# RL6955_IP_SVD register map
Vendor: Realtek
Registers are 32-bit, read-write, reset 0x0 unless marked. A register's access mark holds for its fields unless they carry their own. Offsets are from the block's base; [hi:lo] are bit positions; <NAME> marks a mode.

## PAGE5_ON
Base 0x40000000
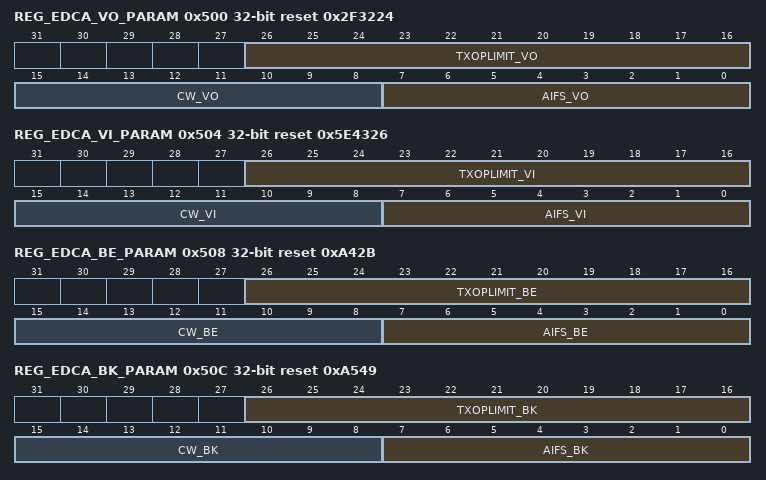
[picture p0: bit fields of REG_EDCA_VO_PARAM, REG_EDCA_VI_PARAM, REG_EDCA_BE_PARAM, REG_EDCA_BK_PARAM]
0x500 REG_EDCA_VO_PARAM reset 0x2F3224
  [26:16] TXOPLIMIT_VO — TXOP Limit An unsigned integer in units of 32 microseconds. Value of zero indicates that a single MSDU or MMPDU in addition to a protection frame exchange can be transmitted at any rate. Default: BK = 0h; BE = 0h; VI = 5Eh; VO = 2Fh.
  [15:8] CW_VO — ECWmin and ECWmax encode the values of Cwmin and Cwmax respectively in an exponent form. Ex: Cwmax = 2^(ECWmax)-1 Default: BK = Ah/5h; BE = Ah/5h; VI = 5h/4h; VO = 4h/3h.
  [7:0] AIFS_VO — Arbitrary Inter frame space In unit of microsecond. AIFS indicates the time a non-AP QSTA should defer before either invoking a backoff or starting a transmission Default: BK = 49h; BE = 25h; VI = 1Ch; VO = 1Ch.
0x504 REG_EDCA_VI_PARAM reset 0x5E4326
  [26:16] TXOPLIMIT_VI — TXOP Limit An unsigned integer in units of 32 microseconds. Value of zero indicates that a single MSDU or MMPDU in addition to a protection frame exchange can be transmitted at any rate. Default: BK = 0h; BE = 0h; VI = 5Eh; VO = 2Fh.
  [15:8] CW_VI — ECWmin and ECWmax encode the values of Cwmin and Cwmax respectively in an exponent form. Ex: Cwmax = 2^(ECWmax)-1 Default: BK = Ah/5h; BE = Ah/5h; VI = 5h/4h; VO = 4h/3h.
  [7:0] AIFS_VI — Arbitrary Inter frame space In unit of microsecond. AIFS indicates the time a non-AP QSTA should defer before either invoking a backoff or starting a transmission Default: BK = 49h; BE = 25h; VI = 1Ch; VO = 1Ch.
0x508 REG_EDCA_BE_PARAM reset 0xA42B
  [26:16] TXOPLIMIT_BE — TXOP Limit An unsigned integer in units of 32 microseconds. Value of zero indicates that a single MSDU or MMPDU in addition to a protection frame exchange can be transmitted at any rate. Default: BK = 0h; BE = 0h; VI = 5Eh; VO = 2Fh.
  [15:8] CW_BE — ECWmin and ECWmax encode the values of Cwmin and Cwmax respectively in an exponent form. Ex: Cwmax = 2^(ECWmax)-1 Default: BK = Ah/5h; BE = Ah/5h; VI = 5h/4h; VO = 4h/3h.
  [7:0] AIFS_BE — Arbitrary Inter frame space In unit of microsecond. AIFS indicates the time a non-AP QSTA should defer before either invoking a backoff or starting a transmission Default: BK = 49h; BE = 25h; VI = 1Ch; VO = 1Ch.
0x50C REG_EDCA_BK_PARAM reset 0xA549
  [26:16] TXOPLIMIT_BK — TXOP Limit An unsigned integer in units of 32 microseconds. Value of zero indicates that a single MSDU or MMPDU in addition to a protection frame exchange can be transmitted at any rate. Default: BK = 0h; BE = 0h; VI = 5Eh; VO = 2Fh.
  [15:8] CW_BK — ECWmin and ECWmax encode the values of Cwmin and Cwmax respectively in an exponent form. Ex: Cwmax = 2^(ECWmax)-1 Default: BK = Ah/5h; BE = Ah/5h; VI = 5h/4h; VO = 4h/3h.
  [7:0] AIFS_BK — Arbitrary Inter frame space In unit of microsecond. AIFS indicates the time a non-AP QSTA should defer before either invoking a backoff or starting a transmission Default: BK = 49h; BE = 25h; VI = 1Ch; VO = 1Ch.
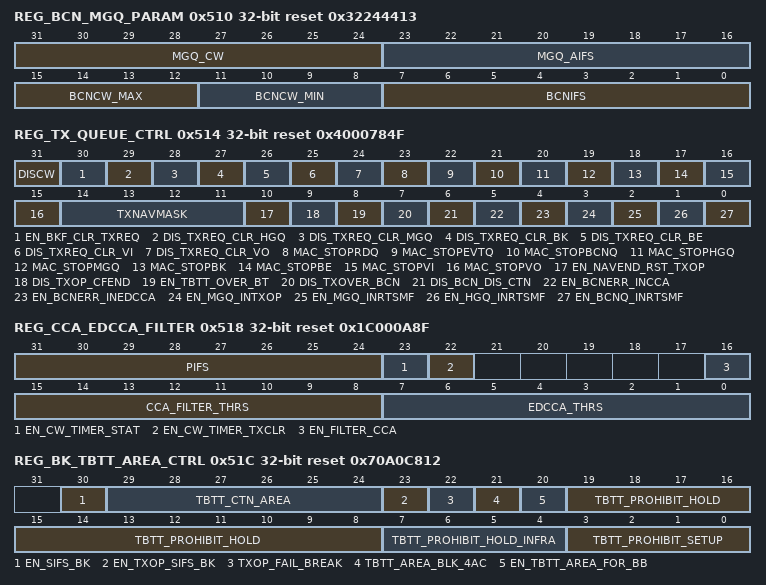
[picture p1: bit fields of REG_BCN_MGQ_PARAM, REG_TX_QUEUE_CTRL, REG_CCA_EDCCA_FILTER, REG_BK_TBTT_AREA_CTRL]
0x510 REG_BCN_MGQ_PARAM reset 0x32244413
  [31:24] MGQ_CW — ECWmin and ECWmax encode the values of Cwmin and Cwmax respectively in an exponent form. Ex: Cwmax = 2^(ECWmax)-1 Default: BK = Ah/5h; BE = Ah/5h; VI = 5h/4h; VO = 4h/3h.
  [23:16] MGQ_AIFS — Arbitrary Inter frame space In unit of microsecond. AIFS indicates the time a non-AP QSTA should defer before either invoking a backoff or starting a transmission Default: BK = 49h; BE = 25h; VI = 1Ch; VO = 1Ch
  [15:12] BCNCW_MAX — Beacon Contention Window MAX Defines the contention window value for back off before transmitting beacon frame. This field is set to 0 in AP mode to indicate no back off window. In ad hoc mode, its default value is 6. 26-1 = 63 time slots.
  [11:8] BCNCW_MIN — Beacon Contention Window Defines the contention window value for back off before transmitting beacon frame. This field is set to 0 in AP mode to indicate no back off window. In ad hoc mode, its default value is 6. 26-1 = 63 time slots.
  [7:0] BCNIFS — Beacon Interframe Space In units of microseconds, this register defines the medium idle time required before transmitting beacon (AP mode) or entering random back off window.
0x514 REG_TX_QUEUE_CTRL reset 0x4000784F
  [31] DISCW — When this bit is set, disable CW.
  [30] EN_BKF_CLR_TXREQ — when gen tx command done, while will backoff is invalid, then tx command will be cleared
  [29] DIS_TXREQ_CLR_HGQ — 1: if this queue can't own channel ,txcmd will be cleared 0:Only TX_finish can clear txreq
  [28] DIS_TXREQ_CLR_MGQ — 1: if this queue can't own channel ,txcmd will be cleared 0:Only TX_finish can clear txreq
  [27] DIS_TXREQ_CLR_BK — 0: if this queue can't own channel ,txcmd will be cleared 1:Only TX_finish can clear txreq
  [26] DIS_TXREQ_CLR_BE — 0: if this queue can't own channel ,txcmd will be cleared 1:Only TX_finish can clear txreq
  [25] DIS_TXREQ_CLR_VI — 0: if this queue can't own channel ,txcmd will be cleared 1:Only TX_finish can clear txreq
  [24] DIS_TXREQ_CLR_VO — 0: if this queue can't own channel ,txcmd will be cleared 1:Only TX_finish can clear txreq
  [23] MAC_STOPRDQ — Stop BCNQ Queue Write a 1 to this bit via software to immediately stop the transmission of packet from this queue including retry attempts.
  [22] MAC_STOPEVTQ — Stop BCNQ Queue Write a 1 to this bit via software to immediately stop the transmission of packet from this queue including retry attempts.
  [21] MAC_STOPBCNQ — Stop BCNQ Queue Write a 1 to this bit via software to immediately stop the transmission of packet from this queue including retry attempts.
  [20] MAC_STOPHGQ — Stop High Queue Write a 1 to this bit via software to immediately stop the transmission of packet from this queue including retry attempts.
  [19] MAC_STOPMGQ — Stop Management Queue Write a 1 to this bit via software to immediately stop the transmission of packet from this queue including retry attempts.
  [18] MAC_STOPBK — Stop BK Queue Write a 1 to this bit via software to immediately stop the transmission of packet from this queue including retry attempts.
  [17] MAC_STOPBE — Stop BE Queue Write a 1 to this bit via software to immediately stop the transmission of packet from this queue including retry attempts.
  [16] MAC_STOPVI — Stop VI Queue Write a 1 to this bit via software to immediately stop the transmission of packet from this queue including retry attempts.
  [15] MAC_STOPVO — Stop VO Queue Write a 1 to this bit via software to immediately stop the transmission of packet from this queue including retry attempts.
  [14:11] TXNAVMASK — 1: Queue BKF must wait TX Nav finished 0: Queue not need wait
  [10] EN_NAVEND_RST_TXOP — When set this bit, TXOP will be reset while NAV end.
  [9] DIS_TXOP_CFEND — Disable TXOP_CFE function
  [8] EN_TBTT_OVER_BT — 1: Enable Beacon Tx at TBTT if BT_CCA is enabled 0: Disable
  [7] DIS_TXOVER_BCN — 1: Tx Packet with ignoring Beacon Area time 0: Disable
  [6] DIS_BCN_DIS_CTN — Disable the Beacon queue disable contention,when set to 0 enable the force beacon function.
  [5] EN_BCNERR_INCCA — eneble force tx becon ignore CCA in disable contention area
  [4] EN_BCNERR_INEDCCA — eneble force tx becon ignore EDCCA in disable contention area
  [3] EN_MGQ_INTXOP — When this bit is set, MGTQ may sent packets by using ACQ TXOP.
  [2] EN_MGQ_INRTSMF — When this bit is set, MTGQ will be TX, not wait until RTS or MF transaction finished.
  [1] EN_HGQ_INRTSMF — When this bit is set, High Q will be TX, not wait until RTS or MF transaction finished.
  [0] EN_BCNQ_INRTSMF — When this bit is set, BCNQ will be TX, not wait until RTS or MF transaction finished.
0x518 REG_CCA_EDCCA_FILTER reset 0x1C000A8F
  [31:24] PIFS — PIFS time. It is only used in AP mode and in units of us.
  [23] EN_CW_TIMER_STAT — 1: enable contention time statistic of ACQ
  [22] EN_CW_TIMER_TXCLR — 1: clear cw timer when any queue tx 0: don't clear cw timer when other queue tx
  [16] EN_FILTER_CCA — Enable CCA filter threshold
  [15:8] CCA_FILTER_THRS — If PHY_CCA signal width is bigger than this threshold, this PHY_CCA signal is valid for MAC. Unit: us
  [7:0] EDCCA_THRS — EDCCA threshold value, edcca over this threshold will cause bkf_rst Bit[7]: PHY_EDCCA為1時,當timer timeout時擋住TX Bit[6:0]: timer (單位:32us)
0x51C REG_BK_TBTT_AREA_CTRL reset 0x70A0C812
  [30] EN_SIFS_BK — SIFS Break Check Criteria enable for AMPDU aggregation, for normal AGGR case
  [29:24] TBTT_CTN_AREA — TBTT contention area,Time unit is 128us,for PORT 1 / 2
  [23] EN_TXOP_SIFS_BK — SIFS Break Check Criteria enable for AMPDU aggregation, VALID when TXOP or RTS HOLD
  [22] TXOP_FAIL_BREAK — 1: if tx pkt fail in txop, then tx cfend to end txop
  [21] TBTT_AREA_BLK_4AC — When set this bit, 4AC backoff is disabled on TBTT setup period
  [20] EN_TBTT_AREA_FOR_BB — enable notify bb that mac p0 is in tbtt area
  [19:8] TBTT_PROHIBIT_HOLD — TBTT_prohibit_hold time for AP mode, unit is 32 us
  [7:4] TBTT_PROHIBIT_HOLD_INFRA — TBTT_prohibit_hold time for infrastructure mode , unit is 2 ms
  [3:0] TBTT_PROHIBIT_SETUP — TBTT_prohibit_setup, unit is 32us; If en nan-CG, this value should be set to 0x06.
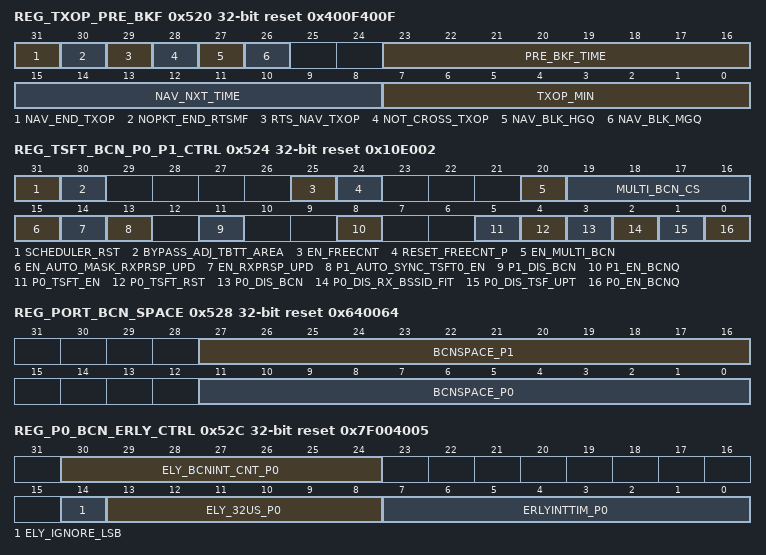
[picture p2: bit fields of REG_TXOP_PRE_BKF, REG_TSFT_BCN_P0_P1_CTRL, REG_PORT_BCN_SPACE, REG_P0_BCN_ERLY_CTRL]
0x520 REG_TXOP_PRE_BKF reset 0x400F400F
  [31] NAV_END_TXOP — 1: In txop mode, Nav protect all txop 0: In txop mode, Nav protect to next pkt
  [30] NOPKT_END_RTSMF — 1: enable exit rts hold mode when there is no corresponding ac pkt to tx
  [29] RTS_NAV_TXOP — enable RTS NAV protect all txop
  [28] NOT_CROSS_TXOP — 1:tx pkt cross tbtt is prohibited 0:tx pkt cross tbtt is permitted
  [27] NAV_BLK_HGQ — rxnav block HGQ
  [26] NAV_BLK_MGQ — rxnav block MGQ
  [23:16] PRE_BKF_TIME — when bkf timer count down this value, sel queue and gen txcmd will start. Unit: 1us
  [15:8] NAV_NXT_TIME — In TXOP mode ,NAV setting which protects next packets
  [7:0] TXOP_MIN — if txop counter is more than this value, than tx pkt is considered not cross tbtt. Unit: 1us
0x524 REG_TSFT_BCN_P0_P1_CTRL access per field reset 0x10E002
  [31] SCHEDULER_RST wo — Write this bit reset scheduler, ioreg_txfail
  [30] BYPASS_ADJ_TBTT_AREA rw — 0: Fixed an issue where tbtt_area kept pulling higher caused by tbtt_int miss 1: follow the original practice
  [25] EN_FREECNT rw — enable freerun tsft
  [24] RESET_FREECNT_P wo — reset pulse of freerun tsft
  [20] EN_MULTI_BCN rw — enable multiple beacons of port0~port2
  [19:16] MULTI_BCN_CS ro — indicate which port is tx beacon
  [15] EN_AUTO_MASK_RXPRSP_UPD rw — valid when BIT_EN_RXPRSP_UPD = 1 1: auto disable RXPRSP's tsft update when rx probe response frame during bcn_early to tbtt(for STA mode - P0)
  [14] EN_RXPRSP_UPD rw — 1: enable update tsft when RX probe response frame. (for STA mode - P0)
  [13] P1_AUTO_SYNC_TSFT0_EN rw — when P0 + P1 is concurrent mode, need to assert 1: sync P1's TSFT = P0's TSFT + TSFTF_SYN_OFFSET each time 0: P1's TSFT = P0's TSFT
  [11] P1_DIS_BCN rw — set 1 to mask the beacon early interrupt of port1
  [8] P1_EN_BCNQ rw — When this bit is set, TSF and other beacon related functions are then enabled. 0x700(MACID1)的enable开关
  [5] P0_TSFT_EN rw — 1: enable P0 TSFT counter, when NAN function is disable, P1 used P0 TSFT counter
  [4] P0_TSFT_RST wo — write this bit, bcn0 tsft will auto reset, reset to 1
  [3] P0_DIS_BCN rw — set 1 to mask the beacon early interrupt of port0
  [2] P0_DIS_RX_BSSID_FIT rw — 0:HW will handle rx_beacon 1:HW will ignore rx_beacon_pk
  [1] P0_DIS_TSF_UPT rw — When set, disable port 0 TSF update when beacon frames or probe response frames are received.
  [0] P0_EN_BCNQ rw — enable beacon function. When this bit is set, TSF and other beacon related functions are then enabled. 0x610(MACID)的enable开关
0x528 REG_PORT_BCN_SPACE reset 0x640064
  [27:16] BCNSPACE_P1 — Unit is ms. the beacon space of port1
  [11:0] BCNSPACE_P0 — Unit is ms. the beacon space of port0
0x52C REG_P0_BCN_ERLY_CTRL reset 0x7F004005
  [30:24] ELY_BCNINT_CNT_P0 — Be used in multiple BCNIVL early INT. When this counter =1, multiple BCNIVL early INT will be triggered.
  [14] ELY_IGNORE_LSB — 1:add1ms, add128us, add32us only check tsft[10], tsft[7], tsft[5], ignore LSB 0: add1ms, add128us, add32us check tsft[9:0], tsft[6:0], tsft[4:0] when active
  [13:8] ELY_32US_P0 — the BCN EARLY interrupt find tune with unit 32us. The Total Early time of BCN early interrupt is the ERLYINTTIM x 1ms - EARLY_32us x 32us.
  [7:0] ERLYINTTIM_P0 — Time to send interrupt to notify driver to change beacon content. Time unit is TU. It is used to wake up early at DriverEarlyTime
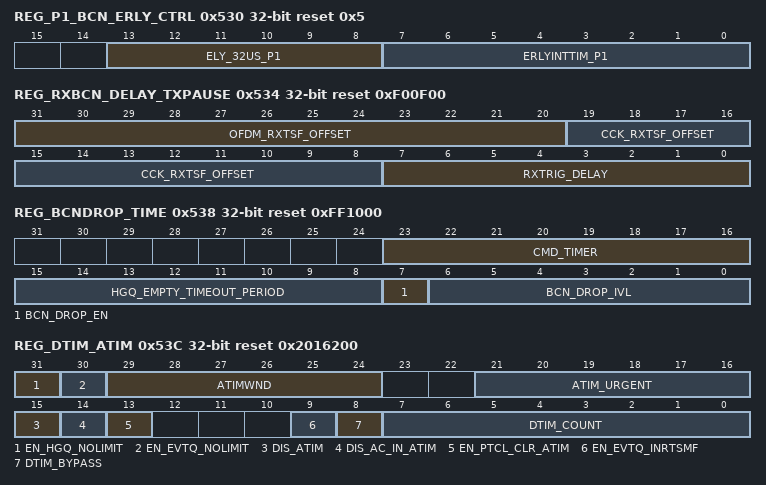
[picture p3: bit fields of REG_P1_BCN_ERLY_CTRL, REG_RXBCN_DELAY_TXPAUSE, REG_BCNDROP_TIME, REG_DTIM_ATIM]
0x530 REG_P1_BCN_ERLY_CTRL reset 0x5
  [13:8] ELY_32US_P1 — the BCN EARLY interrupt find tune with unit 32us. The Total Early time of BCN early interrupt is the ERLYINTTIM x 1ms - EARLY_32us x 32us.
  [7:0] ERLYINTTIM_P1 — Time to send interrupt to notify driver to change beacon content. Time unit is TU. It is used to wake up early at DriverEarlyTime
0x534 REG_RXBCN_DELAY_TXPAUSE reset 0xF00F00
  [31:20] OFDM_RXTSF_OFFSET — The Datapath of OFDM RX_tsf, unit: us
  [19:8] CCK_RXTSF_OFFSET — The Datapath of CCK RX_tsf, unit: us
  [7:0] RXTRIG_DELAY — add compensation of RX trigger's TSFT. Unit: us
0x538 REG_BCNDROP_TIME reset 0xFF1000
  [23:16] CMD_TIMER — When 40M/80M TX CMD ready and secondary_CCA_20/secondary_CCA_40 set for this period, then the TX CMD will be cleared. TU: 1us
  [15:8] HGQ_EMPTY_TIMEOUT_PERIOD — When hgq empty for this period, close atim window. And this will block hgq dma for pcie, unless 0x524[12] set enable. TU: 32us
  [7] BCN_DROP_EN — enable beacon drop function
  [6:0] BCN_DROP_IVL — indicate the timeout of beacon drop
0x53C REG_DTIM_ATIM reset 0x2016200
  [31] EN_HGQ_NOLIMIT — enable no limit mode of hgq
  [30] EN_EVTQ_NOLIMIT — enable no limit mode of evtq
  [29:24] ATIMWND — ATIM window width of P1 TX hgq in units of TU.
  [21:16] ATIM_URGENT — Indicates the time before ATIM Window end. (unit : TU)
  [15] DIS_ATIM — 1: disable assert ATIM
  [14] DIS_AC_IN_ATIM — 1: Disable AC Queue Packet Tx in ATIM (only valid at Nettype: Adhoc/AP) 0: Enable AC Queue packet Tx in ATIM
  [13] EN_PTCL_CLR_ATIM — 1: enable fw_clr_sch_atim signal to clear atimon (means this is the last hgq packet)
  [9] EN_EVTQ_INRTSMF — When this bit is set, Event Q will be TX, not wait until RTS or MF transaction finished.
  [8] DTIM_BYPASS — 1: dtim counter will keep 0
  [7:0] DTIM_COUNT — init dtim value, act on the port of apmode
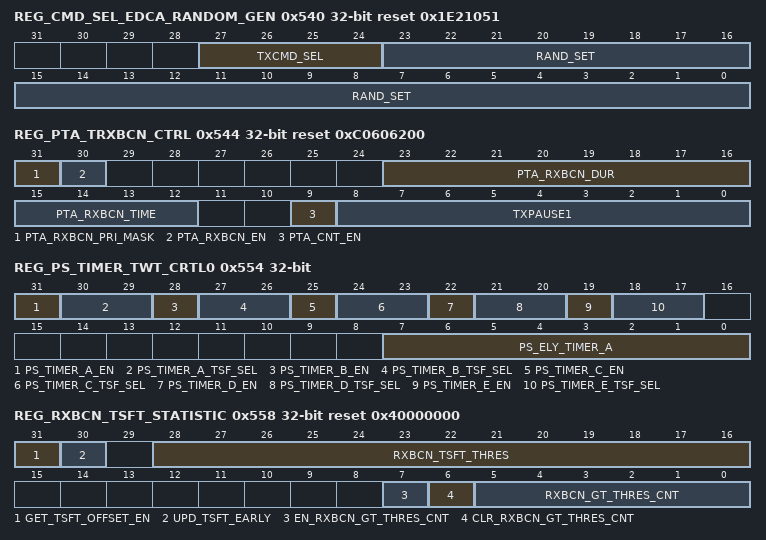
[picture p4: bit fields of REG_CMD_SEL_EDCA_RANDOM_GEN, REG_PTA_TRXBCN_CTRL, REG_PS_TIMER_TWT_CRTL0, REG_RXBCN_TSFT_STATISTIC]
0x540 REG_CMD_SEL_EDCA_RANDOM_GEN reset 0x1E21051
  [27:24] TXCMD_SEL — [HW Debug Info]To select which one TXCMD Segment. For example, 可以在0x5CF[3:0]填 0 or 6 讀取 0x5F8[7:0] : Tx Agg 0x5F9[7:0] : Tx Rate
  [23:0] RAND_SET — Random number generator polynomial
0x544 REG_PTA_TRXBCN_CTRL reset 0xC0606200
  [31] PTA_RXBCN_PRI_MASK
  [30] PTA_RXBCN_EN
  [23:16] PTA_RXBCN_DUR — unit: 32us. Period of wl_rxbcn
  [15:12] PTA_RXBCN_TIME — unit: 32us. Assert wl_rxbcn before TBTT
  [9] PTA_CNT_EN — When change mode, need to count down before exit BT_MODE
  [8:0] TXPAUSE1 — same as 0x514[23:15], allow FW/DR to control pause jointly
0x548 REG_PS_TIMER_A
  [31:0] PS_TIMER_A — When the TSF matches the content of this register, the PS_TIMER_A_INT interrupt is issued. Unit:16us
0x54C REG_PS_TIMER_B
  [31:0] PS_TIMER_B — When the TSF matches the content of this register, the PS_TIMER_B_INT interrupt is issued. Unit:16us
0x550 REG_PS_TIMER_C
  [31:0] PS_TIMER_C — When the TSF matches the content of this register, the PS_TIMER_C_INT interrupt is issued. Unit:16us
0x554 REG_PS_TIMER_TWT_CRTL0
  [31] PS_TIMER_A_EN — Enable PS_TIMER_A
  [30:29] PS_TIMER_A_TSF_SEL — 0 for port 0, 1 for freerun, 2 for p2 backup
  [28] PS_TIMER_B_EN — Enable PS_TIMER_B
  [27:26] PS_TIMER_B_TSF_SEL — 0 for port 0, 1 for freerun, 2 for p2 backup
  [25] PS_TIMER_C_EN — Enable PS_TIMER_C
  [24:23] PS_TIMER_C_TSF_SEL — 0 for port 0, 1 for freerun, 2 for p2 backup
  [22] PS_TIMER_D_EN — Enable PS_TIMER_D
  [21:20] PS_TIMER_D_TSF_SEL — 0 for port 0, 1 for freerun, 2 for p2 backup
  [19] PS_TIMER_E_EN — Enable PS_TIMER_E
  [18:17] PS_TIMER_E_TSF_SEL — 0 for port 0, 1 for freerun, 2 for p2 backup
  [7:0] PS_ELY_TIMER_A — It is used to wake up early at PS_Timer_A_Early Time. Time unit is 32us.
0x558 REG_RXBCN_TSFT_STATISTIC access per field reset 0x40000000
  [31] GET_TSFT_OFFSET_EN rw — 1: Enable Enable get TSFT offset function
  [30] UPD_TSFT_EARLY rw — 0: don't update TSFT when the following scenarios occur: tim_no_hit, |TSFT - rxbcn.timestamp| <= BIT_RXBCN_TSFT_THRES, and r_wait_rxbcn_finish = 1 1: update TSFT
  [28:16] RXBCN_TSFT_THRES rw — used for LPS MAC, if |TSFT - rxbcn.timestamp| > BIT_RXBCN_TSFT_THRES, need to wait fcsok. Else, update TSFT at wmac_rxtsf_rdy (before fcsok) unit is 1us,max is 8ms
  [7] EN_RXBCN_GT_THRES_CNT rw — enable the counter of BIT_RXBCN_GT_THRES_CNT
  [6] CLR_RXBCN_GT_THRES_CNT wo — clear the BIT_RXBCN_GT_THRES_CNT to 0
  [5:0] RXBCN_GT_THRES_CNT ro — valid when BIT_EN_RXBCN_GT_THRES_CNT = 1. counter the number of beacon with the |TSFT - rxbcn.timestamp| exceed the threshold
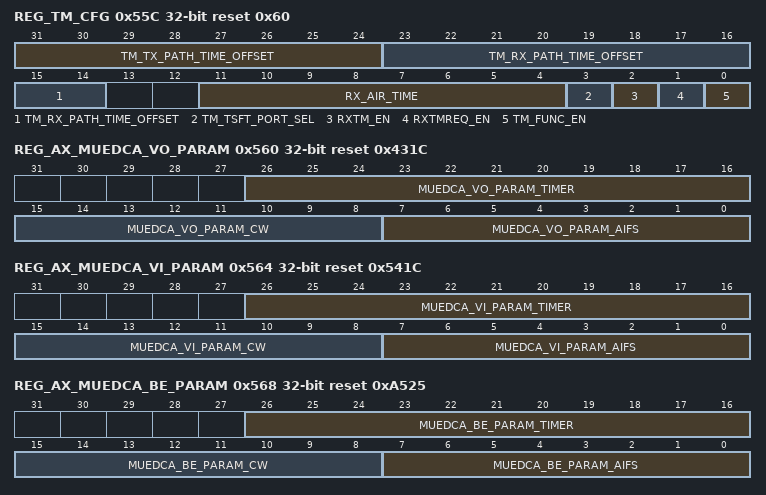
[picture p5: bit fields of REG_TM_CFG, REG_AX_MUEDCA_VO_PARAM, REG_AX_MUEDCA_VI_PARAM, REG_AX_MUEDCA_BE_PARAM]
0x55C REG_TM_CFG reset 0x60
  [31:24] TM_TX_PATH_TIME_OFFSET — Compensate the time, from PHYTXON rising edge to transmit antenna connector. unit: 1us
  [23:14] TM_RX_PATH_TIME_OFFSET — Compensate the time, from receive antenna connector to DATAON rising edge. unit: 1us
  [11:4] RX_AIR_TIME — This register sets the time from cca fall to 6us. unit: 1us. (default:6us)
  [3] TM_TSFT_PORT_SEL — selected TM timer port 0: port0; 1: freerun
  [2] RXTM_EN — 1: HW will parsing rx packet, to find TM frame
  [1] RXTMREQ_EN — 1: HW will parsing rx packet, to find TM request frame
  [0] TM_FUNC_EN — 1: Enable Timing Measurement function
0x560 REG_AX_MUEDCA_VO_PARAM reset 0x431C
  [26:16] MUEDCA_VO_PARAM_TIMER — MU EDCA TIMER, in units of 1ms Note: SPEC: The MU EDCA Timer field (8b) indicates the duration of time, in units of 8 TUs
  [15:8] MUEDCA_VO_PARAM_CW — ECWmin and ECWmax encode the values of Cwmin and Cwmax respectively in an exponent form. Ex: Cwmax = 2^(ECWmax)-1 Default: BK = Ah/5h; BE = Ah/5h; VI = 5h/4h; VO = 4h/3h.
  [7:0] MUEDCA_VO_PARAM_AIFS — Arbitrary Inter frame space In unit of microsecond. AIFS indicates the time a non-AP QSTA should defer before either invoking a backoff or starting a transmission Default: BK = 49h; BE = 25h; VI = 1Ch; VO = 1Ch.
0x564 REG_AX_MUEDCA_VI_PARAM reset 0x541C
  [26:16] MUEDCA_VI_PARAM_TIMER — MU EDCA TIMER, in units of 1ms Note: SPEC: The MU EDCA Timer field (8b) indicates the duration of time, in units of 8 TUs
  [15:8] MUEDCA_VI_PARAM_CW — ECWmin and ECWmax encode the values of Cwmin and Cwmax respectively in an exponent form. Ex: Cwmax = 2^(ECWmax)-1 Default: BK = Ah/5h; BE = Ah/5h; VI = 5h/4h; VO = 4h/3h.
  [7:0] MUEDCA_VI_PARAM_AIFS — Arbitrary Inter frame space In unit of microsecond. AIFS indicates the time a non-AP QSTA should defer before either invoking a backoff or starting a transmission Default: BK = 49h; BE = 25h; VI = 1Ch; VO = 1Ch.
0x568 REG_AX_MUEDCA_BE_PARAM reset 0xA525
  [26:16] MUEDCA_BE_PARAM_TIMER — MU EDCA TIMER, in units of 1ms Note: SPEC: The MU EDCA Timer field (8b) indicates the duration of time, in units of 8 TUs
  [15:8] MUEDCA_BE_PARAM_CW — ECWmin and ECWmax encode the values of Cwmin and Cwmax respectively in an exponent form. Ex: Cwmax = 2^(ECWmax)-1 Default: BK = Ah/5h; BE = Ah/5h; VI = 5h/4h; VO = 4h/3h.
  [7:0] MUEDCA_BE_PARAM_AIFS — Arbitrary Inter frame space In unit of microsecond. AIFS indicates the time a non-AP QSTA should defer before either invoking a backoff or starting a transmission Default: BK = 49h; BE = 25h; VI = 1Ch; VO = 1Ch.
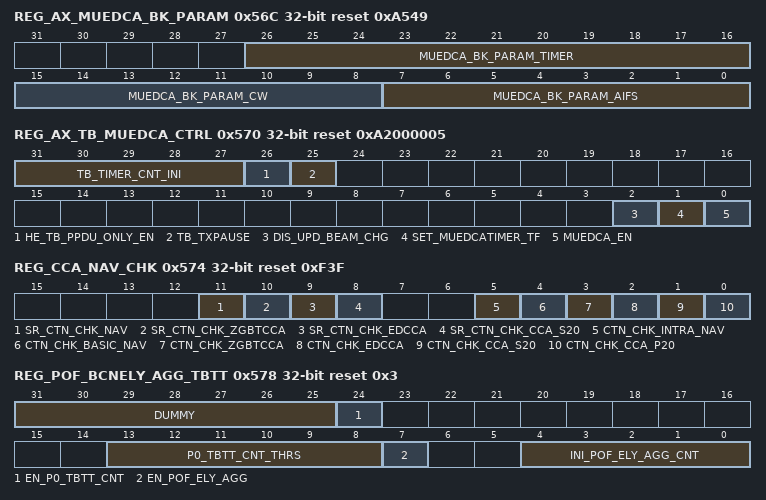
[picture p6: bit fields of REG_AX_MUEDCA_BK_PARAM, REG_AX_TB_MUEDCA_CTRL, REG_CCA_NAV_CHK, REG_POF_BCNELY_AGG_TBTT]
0x56C REG_AX_MUEDCA_BK_PARAM reset 0xA549
  [26:16] MUEDCA_BK_PARAM_TIMER — MU EDCA TIMER, in units of 1ms Note: SPEC: The MU EDCA Timer field (8b) indicates the duration of time, in units of 8 TUs
  [15:8] MUEDCA_BK_PARAM_CW — ECWmin and ECWmax encode the values of Cwmin and Cwmax respectively in an exponent form. Ex: Cwmax = 2^(ECWmax)-1 Default: BK = Ah/5h; BE = Ah/5h; VI = 5h/4h; VO = 4h/3h.
  [7:0] MUEDCA_BK_PARAM_AIFS — Arbitrary Inter frame space In unit of microsecond. AIFS indicates the time a non-AP QSTA should defer before either invoking a backoff or starting a transmission Default: BK = 49h; BE = 25h; VI = 1Ch; VO = 1Ch.
0x570 REG_AX_TB_MUEDCA_CTRL reset 0xA2000005
  [31:27] TB_TIMER_CNT_INI — the initial value of th_timer, unit: us
  [26] HE_TB_PPDU_ONLY_EN — asserted if the TWT is trigger-enabled TWT
  [25] TB_TXPAUSE — valid if BIT_HE_TB_PPSU_ONLY_EN = 1; select pause edca or not during TWT-SP; default is 1, pause. A TWT requesting STA should not transmit frames to the TWT responding STA outside of negotiated TWT SPs and should not transmit frames that are not contained within HE TB PPDUs to the TWT responding STA within trigger-enabled TWT SPs
  [2] DIS_UPD_BEAM_CHG — 1: txcmd_beam_change TIE 0 0: first PPDU in TXOP will assert txcmd_beam_change
  [1] SET_MUEDCATIMER_TF — 1: enable HW updating MUEDCATimer after Tx HE TB PPDU 0: disable HW updating MUEDCATimer after Tx HE TB PPDU
  [0] MUEDCA_EN — 1: enable HW updating MUEDCATimer 0: disable HW updating MUEDCATimer
0x574 REG_CCA_NAV_CHK reset 0xF3F
  [11] SR_CTN_CHK_NAV — When BASIC or INTRA NAV > 0 in the AIFS/Backoff before active TX 0: Can backoff, can TX 1: Cannot backoff, cannot TX
  [10] SR_CTN_CHK_ZGBTCCA — When ~GNT_WL(BT/ZigBee) assert in the AIFS/Backoff before active TX 0: Can backoff, can TX 1: Cannot backoff, cannot TX
  [9] SR_CTN_CHK_EDCCA — When EDCCA assert in the AIFS/Backoff before active TX 0: Can backoff, can TX 1: Cannot backoff, cannot TX
  [8] SR_CTN_CHK_CCA_S20 — When EDCCA assert in the AIFS/Backoff before active TX 0: Can backoff, can TX 1: Cannot backoff, cannot TX
  [5] CTN_CHK_INTRA_NAV — When INTRA NAV > 0 in the AIFS/Backoff before active TX 0: Can backoff, can TX 1: Cannot backoff, cannot TX
  [4] CTN_CHK_BASIC_NAV — When BASIC NAV > 0 in the AIFS/Backoff before active TX 0: Can backoff, can TX 1: Cannot backoff, cannot TX
  [3] CTN_CHK_ZGBTCCA — When ~GNT_WL(BT/ZigBee) assert in the AIFS/Backoff before active TX 0: Can backoff, can TX 1: Cannot backoff, cannot TX
  [2] CTN_CHK_EDCCA — When EDCCA assert in the AIFS/Backoff before active TX 0: Can backoff, can TX 1: Cannot backoff, cannot TX
  [1] CTN_CHK_CCA_S20 — When SECONDARY_CCA_20 assert in the AIFS/Backoff before active TX 0: Can backoff, can TX 1: Can backoff, cannot TX
  [0] CTN_CHK_CCA_P20 — When CCA assert in the AIFS/Backoff before active TX 0: Can backoff, can TX 1: Cannot backoff, cannot TX
0x578 REG_POF_BCNELY_AGG_TBTT reset 0x3
  [31:25] DUMMY
  [24] EN_P0_TBTT_CNT — enable the tbtt counter function.
  [13:8] P0_TBTT_CNT_THRS — P0's TBTT counter threshold . Valid when BIT_EN_P0_TBTT_CNT = 1. when tbtt_cnt >= BIT_P0_TBTT_CNT_THRS, assert p0_tbtt_agg_int. UNIT: 16
  [7] EN_POF_ELY_AGG — update bcn_ely_agg initial value of P0 to BIT_INI_POF_ELY_AGG_CNT 1: enable 0: disable
  [4:0] INI_POF_ELY_AGG_CNT — bcn_ely_agg initial value of P0. Valid when BIT_EN_POF_ELY_AGG = 1
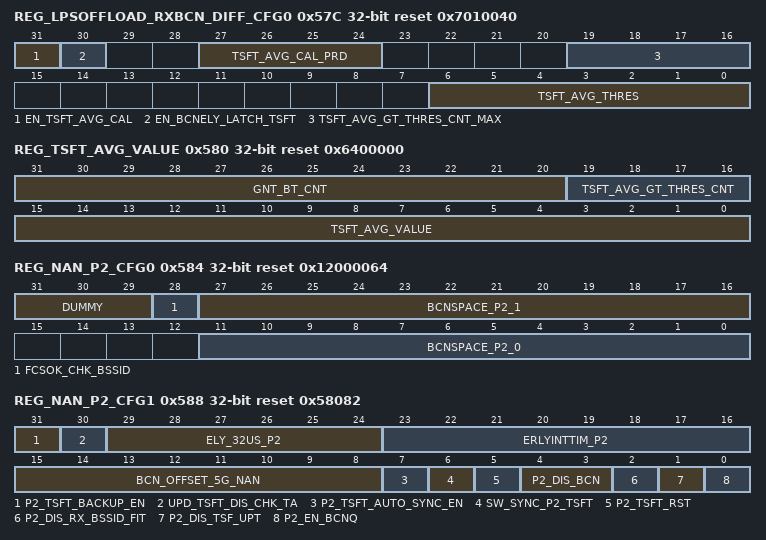
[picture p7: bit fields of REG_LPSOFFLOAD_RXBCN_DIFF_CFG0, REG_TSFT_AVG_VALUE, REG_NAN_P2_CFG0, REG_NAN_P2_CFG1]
0x57C REG_LPSOFFLOAD_RXBCN_DIFF_CFG0 reset 0x7010040
  [31] EN_TSFT_AVG_CAL — 1: calculate the average value of deltaTSFT(latch hioe_int_chn_on and cca_up) in specified period
  [30] EN_BCNELY_LATCH_TSFT — 1: latch TSFT to BIT_TSFT_AT_HIOE_RFON (0x153C) when P0's bcn_early int asserted
  [27:24] TSFT_AVG_CAL_PRD — 2^(BIT_TSFT_AVG_CAL_PERIOD), default is 128 times
  [19:16] TSFT_AVG_GT_THRES_CNT_MAX — The max times of the BIT_TSFT_AVG_VALUE greater than BIT_TSFT_AVG_THRES, if the BIT_TSFT_AVG_VALUE exceeds the BIT_TSFT_AVG_THRES several times in a row, and the number exceeds the BIT_TSFT_AVG_GT_THRES_CNT_MAX, generate an interrupt
  [6:0] TSFT_AVG_THRES — The threshold of deltaTSFT(latch hioe_int_chn_on and cca_up), unit 32us
0x580 REG_TSFT_AVG_VALUE access per field reset 0x6400000
  [31:20] GNT_BT_CNT rw — WIFI TX shall wait settle time when antenna is switched from BT to WIFI/RADAR, if the BT use the same RFAFE as WIFI. Unit: 1us
  [19:16] TSFT_AVG_GT_THRES_CNT ro — statistic the times of the BIT_TSFT_AVG_VALUE than BIT_TSFT_AVG_THRES
  [15:0] TSFT_AVG_VALUE ro — the average value of deltaTSFT(latch hioe_int_chn_on and cca_up) in specified period
0x584 REG_NAN_P2_CFG0 reset 0x12000064
  [31:29] DUMMY
  [28] FCSOK_CHK_BSSID — 1:HW will check bssid when fcsok
  [27:16] BCNSPACE_P2_1 — Unit is ms. the beacon space of port2 sync beacon. default is 512ms
  [11:0] BCNSPACE_P2_0 — Unit is ms. the beacon space of port2 disc beacon. default is 100ms
0x588 REG_NAN_P2_CFG1 access per field reset 0x58082
  [31] P2_TSFT_BACKUP_EN rw — 1:en tsft backup
  [30] UPD_TSFT_DIS_CHK_TA rw — 1: don't check TA_FIT when update NAN tsft
  [29:24] ELY_32US_P2 rw — the BCN EARLY interrupt find tune with unit 32us. The Total Early time of BCN early interrupt is the ERLYINTTIM x 1ms - EARLY_32us x 32us.
  [23:16] ERLYINTTIM_P2 rw — Time to send interrupt to notify driver to change beacon content. Time unit is TU. It is used to wake up early at DriverEarlyTime
  [15:8] BCN_OFFSET_5G_NAN rw — Unit is ms. the tbtt offset between 2.4G sync beacon and 5G sync bcn. Default is 128ms
  [7] P2_TSFT_AUTO_SYNC_EN rw — 1: enable HW auto tsft sync, when sync beacon frames are received, auto update RX.timestamp + RX path delay to TSFT_P2_0
  [6] SW_SYNC_P2_TSFT wo — When write this bit, TSFT P2_0 will sync to TSFT P2_1 without TSFTF_SYN_OFFSET, need co-work with BIT_P2_DIS_TSF_UPT = 1
  [5] P2_TSFT_RST wo — write this bit, bcn2 tsft will reset to 1
  [4:3] P2_DIS_BCN rw — set 1 to mask the beacon early interrupt of port2 [0]: for NAN disc beacon [1]: for NAN sync beacon
  [2] P2_DIS_RX_BSSID_FIT rw — 0:HW will handle rx_beacon 1:HW will ignore rx_beacon_pk
  [1] P2_DIS_TSF_UPT rw — When set, disable clint 2 TSF update when beacon frames or probe response frames are received.
  [0] P2_EN_BCNQ rw — When this bit is set, TSF and other beacon related functions are then enabled. BIT_P2_EN_BCNQ = 1 also means turning on the NAN feature
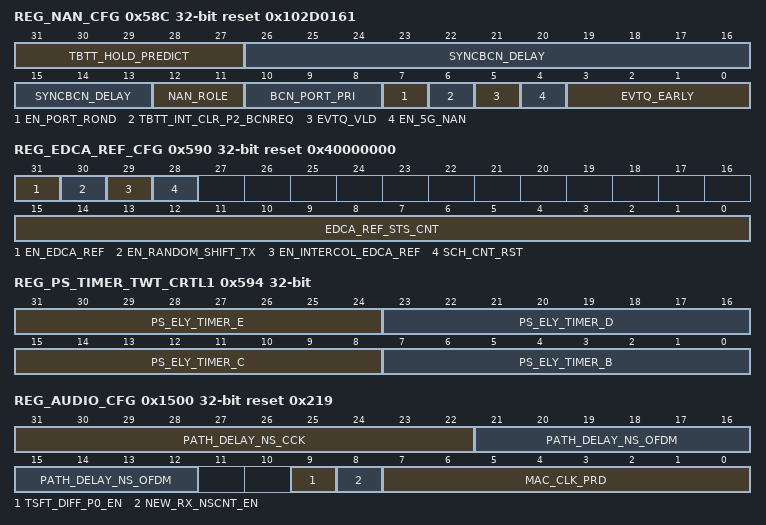
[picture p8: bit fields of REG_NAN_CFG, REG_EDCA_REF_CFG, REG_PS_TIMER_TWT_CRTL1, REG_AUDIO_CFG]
0x58C REG_NAN_CFG reset 0x102D0161
  [31:27] TBTT_HOLD_PREDICT — the predicted hold time after tbtt for P0 RX beacon, unit is 1ms
  [26:13] SYNCBCN_DELAY — r_HC * r_SLOTTIME * 8'd40 (unit:us) default: r_HC = 1, r_SLOTTIME = 9, => 360us max is 16ms (DW)
  [12:11] NAN_ROLE — the role of NAN device: 2'b00: master 2'b01: no-master sync 2'b10: no-master no-sync.
  [10:8] BCN_PORT_PRI — the priority of ports 000: no priority 001: port2 sync bcn has higher priority than P0/P1, P2 sync > P0/P1 010: port0 has higher priority than P2 sync bcn, P0 > P2 sync > P1 011: port1 has higher priority than P2 sync bcn, P1 > P2 sync > P0 100: port0 and port1 has higher priority than P2 sync bcn, P0/P1 > P2 sync
  [7] EN_PORT_ROND — 1: enable round-robin of P2 disc beacon and P0/1 beacon
  [6] TBTT_INT_CLR_P2_BCNREQ — 1: tbtt int can clear bcnely_req when arbitration fail
  [5] EVTQ_VLD — 1: enable EVTQ TX
  [4] EN_5G_NAN — 1: enable 5G NAN mode 0: only 2.4G NAN
  [3:0] EVTQ_EARLY — the early time of evtq tx window. unit is TU
0x590 REG_EDCA_REF_CFG access per field reset 0x40000000
  [31] EN_EDCA_REF rw — When this bit set 1, enable EDCA REF function
  [30] EN_RANDOM_SHIFT_TX rw — When this bit set 1, enable random shift TX function
  [29] EN_INTERCOL_EDCA_REF rw — When this bit set 1, enable inter-collision edca_ref
  [28] SCH_CNT_RST wo — write "1" to set the BIT_EDCA_REF_STS_CNT to zero
  [15:0] EDCA_REF_STS_CNT ro
0x594 REG_PS_TIMER_TWT_CRTL1
  [31:24] PS_ELY_TIMER_E — It is used to wake up early at PS_Timer_E_Early Time. Time unit is 32us.
  [23:16] PS_ELY_TIMER_D — It is used to wake up early at PS_Timer_D_Early Time. Time unit is 32us.
  [15:8] PS_ELY_TIMER_C — It is used to wake up early at PS_Timer_C_Early Time. Time unit is 32us.
  [7:0] PS_ELY_TIMER_B — It is used to wake up early at PS_Timer_B_Early Time. Time unit is 32us.
0x598 REG_PS_TIMER_D
  [31:0] PS_TIMER_D — When the TSF matches the content of this register, the PS_TIMER_B_INT interrupt is issued. Unit:16us
0x59C REG_PS_TIMER_E
  [31:0] PS_TIMER_E — When the TSF matches the content of this register, the PS_TIMER_C_INT interrupt is issued. Unit:16us
0x1500 REG_AUDIO_CFG reset 0x219
  [31:22] PATH_DELAY_NS_CCK — the NS part of RX CCK1M PATH DELAY
  [21:12] PATH_DELAY_NS_OFDM — the NS part of RX OFDM6M PATH DELAY
  [9] TSFT_DIFF_P0_EN — 1:get tsft difference between local tsft and update value when update tsft
  [8] NEW_RX_NSCNT_EN — 1: enable the new ns counter of rx 0: follow old ns counter as tx
  [7:0] MAC_CLK_PRD — set the period of MAC CLK, default 40M - 25ns
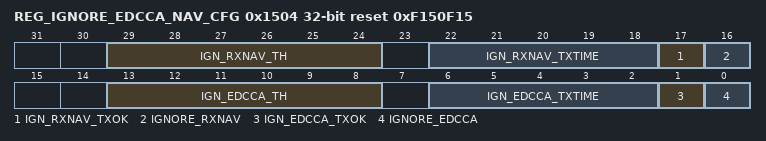
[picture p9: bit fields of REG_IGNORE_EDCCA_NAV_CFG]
0x1504 REG_IGNORE_EDCCA_NAV_CFG reset 0xF150F15
  [29:24] IGN_RXNAV_TH — indicate the threshold of rxnav ignored, unit: 1ms
  [22:18] IGN_RXNAV_TXTIME — indicate the tx times of ignore rxnav tx
  [17] IGN_RXNAV_TXOK — 1: only de-ignore rxnav when tx ok/drop
  [16] IGNORE_RXNAV — 1: backoff ignore rxnav when reach threshold
  [13:8] IGN_EDCCA_TH — indicate the threshold of edcca ignored, unit: 1ms
  [6:2] IGN_EDCCA_TXTIME — indicate the tx times of ignore edcca tx
  [1] IGN_EDCCA_TXOK — 1: only de-ignore edcca when tx ok/drop
  [0] IGNORE_EDCCA — 1: backoff ignore edcca when reach threshold
